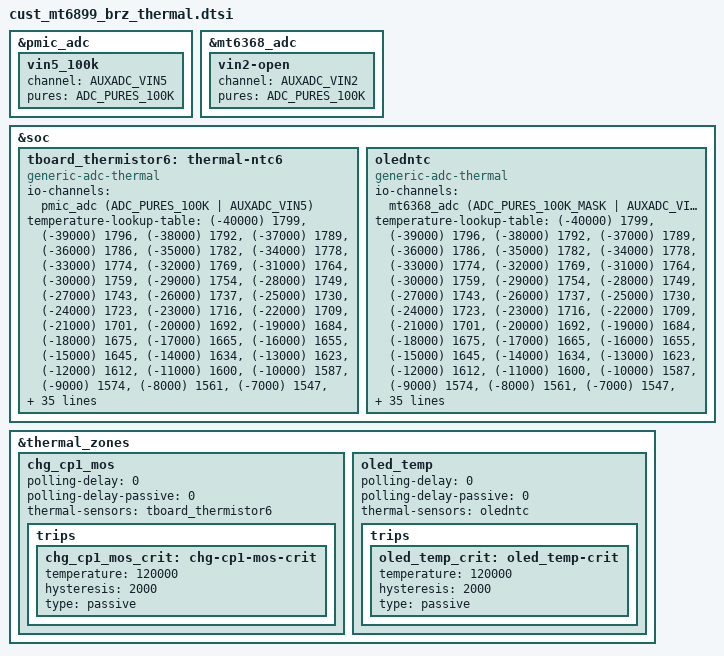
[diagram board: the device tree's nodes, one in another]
// SPDX-License-Identifier: GPL-2.0
/* Copyright (c) 2023 MediaTek Inc. */
#include <dt-bindings/clock/mt6899-clk.h>
#include <dt-bindings/thermal/thermal.h>

&pmic_adc {
	vin5_100k {
		channel = <AUXADC_VIN5>;
		pures = <ADC_PURES_100K>;
	};
};

&mt6368_adc {
	vin2-open {
		channel = <AUXADC_VIN2>;
		pures = <ADC_PURES_100K>;
	};
};

&soc {
    tboard_thermistor6: thermal-ntc6 {
		compatible = "generic-adc-thermal";
		#thermal-sensor-cells = <0>;
		io-channels = <&pmic_adc (ADC_PURES_100K | AUXADC_VIN5)>;
		io-channel-names = "sensor-channel";
		temperature-lookup-table =
			<(-40000) 1799>,
			<(-39000) 1796>,
			<(-38000) 1792>,
			<(-37000) 1789>,
			<(-36000) 1786>,
			<(-35000) 1782>,
			<(-34000) 1778>,
			<(-33000) 1774>,
			<(-32000) 1769>,
			<(-31000) 1764>,
			<(-30000) 1759>,
			<(-29000) 1754>,
			<(-28000) 1749>,
			<(-27000) 1743>,
			<(-26000) 1737>,
			<(-25000) 1730>,
			<(-24000) 1723>,
			<(-23000) 1716>,
			<(-22000) 1709>,
			<(-21000) 1701>,
			<(-20000) 1692>,
			<(-19000) 1684>,
			<(-18000) 1675>,
			<(-17000) 1665>,
			<(-16000) 1655>,
			<(-15000) 1645>,
			<(-14000) 1634>,
			<(-13000) 1623>,
			<(-12000) 1612>,
			<(-11000) 1600>,
			<(-10000) 1587>,
			<(-9000) 1574>,
			<(-8000) 1561>,
			<(-7000) 1547>,
			<(-6000) 1532>,
			<(-5000) 1518>,
			<(-4000) 1502>,
			<(-3000) 1487>,
			<(-2000) 1471>,
			<(-1000) 1454>,
			<0 1437>,
			<1000 1419>,
			<2000 1402>,
			<3000 1383>,
			<4000 1365>,
			<5000 1346>,
			<6000 1326>,
			<7000 1306>,
			<8000 1286>,
			<9000 1266>,
			<10000 1245>,
			<11000 1225>,
			<12000 1203>,
			<13000 1182>,
			<14000 1161>,
			<15000 1139>,
			<16000 1117>,
			<17000 1095>,
			<18000 1073>,
			<19000 1051>,
			<20000 1029>,
			<21000 1007>,
			<22000 985>,
			<23000 963>,
			<24000 941>,
			<25000 920>,
			<26000 898>,
			<27000 876>,
			<28000 855>,
			<29000 834>,
			<30000 813>,
			<31000 792>,
			<32000 772>,
			<33000 751>,
			<34000 731>,
			<35000 712>,
			<36000 692>,
			<37000 673>,
			<38000 655>,
			<39000 636>,
			<40000 618>,
			<41000 601>,
			<42000 583>,
			<43000 566>,
			<44000 550>,
			<45000 534>,
			<46000 518>,
			<47000 502>,
			<48000 487>,
			<49000 472>,
			<50000 458>,
			<51000 444>,
			<52000 430>,
			<53000 417>,
			<54000 404>,
			<55000 392>,
			<56000 380>,
			<57000 368>,
			<58000 356>,
			<59000 345>,
			<60000 334>,
			<61000 324>,
			<62000 313>,
			<63000 303>,
			<64000 294>,
			<65000 284>,
			<66000 275>,
			<67000 267>,
			<68000 258>,
			<69000 250>,
			<70000 242>,
			<71000 234>,
			<72000 227>,
			<73000 220>,
			<74000 213>,
			<75000 206>,
			<76000 199>,
			<77000 193>,
			<78000 187>,
			<79000 181>,
			<80000 175>,
			<81000 170>,
			<82000 164>,
			<83000 159>,
			<84000 154>,
			<85000 149>,
			<86000 145>,
			<87000 140>,
			<88000 136>,
			<89000 132>,
			<90000 128>,
			<91000 124>,
			<92000 120>,
			<93000 116>,
			<94000 113>,
			<95000 109>,
			<96000 106>,
			<97000 103>,
			<98000 99>,
			<99000 96>,
			<100000 94>,
			<101000 91>,
			<102000 88>,
			<103000 85>,
			<104000 83>,
			<105000 80>,
			<106000 78>,
			<107000 76>,
			<108000 73>,
			<109000 71>,
			<110000 69>,
			<111000 67>,
			<112000 65>,
			<113000 63>,
			<114000 61>,
			<115000 60>,
			<116000 58>,
			<117000 56>,
			<118000 55>,
			<119000 53>,
			<120000 52>,
			<121000 50>,
			<122000 49>,
			<123000 47>,
			<124000 46>,
			<125000 45>;
	};

	oledntc: oledntc {
		compatible = "generic-adc-thermal";
		#thermal-sensor-cells = <0>;
		io-channels = <&mt6368_adc (ADC_PURES_100K_MASK | AUXADC_VIN2)>;
		io-channel-names = "sensor-channel";
		temperature-lookup-table =
			<(-40000) 1799>,
			<(-39000) 1796>,
			<(-38000) 1792>,
			<(-37000) 1789>,
			<(-36000) 1786>,
			<(-35000) 1782>,
			<(-34000) 1778>,
			<(-33000) 1774>,
			<(-32000) 1769>,
			<(-31000) 1764>,
			<(-30000) 1759>,
			<(-29000) 1754>,
			<(-28000) 1749>,
			<(-27000) 1743>,
			<(-26000) 1737>,
			<(-25000) 1730>,
			<(-24000) 1723>,
			<(-23000) 1716>,
			<(-22000) 1709>,
			<(-21000) 1701>,
			<(-20000) 1692>,
			<(-19000) 1684>,
			<(-18000) 1675>,
			<(-17000) 1665>,
			<(-16000) 1655>,
			<(-15000) 1645>,
			<(-14000) 1634>,
			<(-13000) 1623>,
			<(-12000) 1612>,
			<(-11000) 1600>,
			<(-10000) 1587>,
			<(-9000) 1574>,
			<(-8000) 1561>,
			<(-7000) 1547>,
			<(-6000) 1532>,
			<(-5000) 1518>,
			<(-4000) 1502>,
			<(-3000) 1487>,
			<(-2000) 1471>,
			<(-1000) 1454>,
			<0 1437>,
			<1000 1419>,
			<2000 1402>,
			<3000 1383>,
			<4000 1365>,
			<5000 1346>,
			<6000 1326>,
			<7000 1306>,
			<8000 1286>,
			<9000 1266>,
			<10000 1245>,
			<11000 1225>,
			<12000 1203>,
			<13000 1182>,
			<14000 1161>,
			<15000 1139>,
			<16000 1117>,
			<17000 1095>,
			<18000 1073>,
			<19000 1051>,
			<20000 1029>,
			<21000 1007>,
			<22000 985>,
			<23000 963>,
			<24000 941>,
			<25000 920>,
			<26000 898>,
			<27000 876>,
			<28000 855>,
			<29000 834>,
			<30000 813>,
			<31000 792>,
			<32000 772>,
			<33000 751>,
			<34000 731>,
			<35000 712>,
			<36000 692>,
			<37000 673>,
			<38000 655>,
			<39000 636>,
			<40000 618>,
			<41000 601>,
			<42000 583>,
			<43000 566>,
			<44000 550>,
			<45000 534>,
			<46000 518>,
			<47000 502>,
			<48000 487>,
			<49000 472>,
			<50000 458>,
			<51000 444>,
			<52000 430>,
			<53000 417>,
			<54000 404>,
			<55000 392>,
			<56000 380>,
			<57000 368>,
			<58000 356>,
			<59000 345>,
			<60000 334>,
			<61000 324>,
			<62000 313>,
			<63000 303>,
			<64000 294>,
			<65000 284>,
			<66000 275>,
			<67000 267>,
			<68000 258>,
			<69000 250>,
			<70000 242>,
			<71000 234>,
			<72000 227>,
			<73000 220>,
			<74000 213>,
			<75000 206>,
			<76000 199>,
			<77000 193>,
			<78000 187>,
			<79000 181>,
			<80000 175>,
			<81000 170>,
			<82000 164>,
			<83000 159>,
			<84000 154>,
			<85000 149>,
			<86000 145>,
			<87000 140>,
			<88000 136>,
			<89000 132>,
			<90000 128>,
			<91000 124>,
			<92000 120>,
			<93000 116>,
			<94000 113>,
			<95000 109>,
			<96000 106>,
			<97000 103>,
			<98000 99>,
			<99000 96>,
			<100000 94>,
			<101000 91>,
			<102000 88>,
			<103000 85>,
			<104000 83>,
			<105000 80>,
			<106000 78>,
			<107000 76>,
			<108000 73>,
			<109000 71>,
			<110000 69>,
			<111000 67>,
			<112000 65>,
			<113000 63>,
			<114000 61>,
			<115000 60>,
			<116000 58>,
			<117000 56>,
			<118000 55>,
			<119000 53>,
			<120000 52>,
			<121000 50>,
			<122000 49>,
			<123000 47>,
			<124000 46>,
			<125000 45>;
	};
};

&thermal_zones {
	chg_cp1_mos: chg_cp1_mos {
		polling-delay = <0>; /* milliseconds */
		polling-delay-passive = <0>; /* milliseconds */
		thermal-sensors = <&tboard_thermistor6>;
		trips {
			chg_cp1_mos_crit: chg-cp1-mos-crit {
				temperature = <120000>;
				hysteresis = <2000>;
				type = "passive";
			};
		};
	};

	oled_temp: oled_temp {
		polling-delay = <0>; /* milliseconds */
		polling-delay-passive = <0>; /* milliseconds */
		thermal-sensors = <&oledntc>;
		trips {
			oled_temp_crit: oled_temp-crit {
				temperature = <120000>;
				hysteresis = <2000>;
				type = "passive";
			};
		};
	};
};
